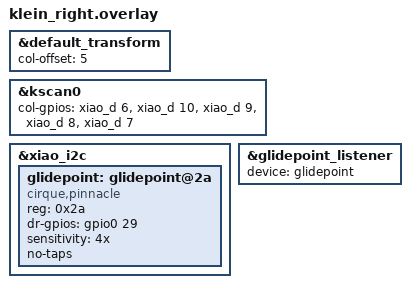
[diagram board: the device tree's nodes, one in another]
/*
 * Copyright (c) 2020 Derek Schmell
 *
 * SPDX-License-Identifier: MIT
 */

#include "klein.dtsi"

&default_transform {
	col-offset = <5>;
};

&kscan0 {
    col-gpios
        = <&xiao_d 6  (GPIO_ACTIVE_HIGH | GPIO_PULL_DOWN)>
        , <&xiao_d 10  (GPIO_ACTIVE_HIGH | GPIO_PULL_DOWN)>
        , <&xiao_d 9  (GPIO_ACTIVE_HIGH | GPIO_PULL_DOWN)>
        , <&xiao_d 8  (GPIO_ACTIVE_HIGH | GPIO_PULL_DOWN)>
        , <&xiao_d 7  (GPIO_ACTIVE_HIGH | GPIO_PULL_DOWN)>
        ;
};

// &xiao_i2c {
//     status = "okay";
//     glidepoint: glidepoint@2a {
//         status = "okay";
//     };
// };

&xiao_i2c {
    status = "okay";
    glidepoint: glidepoint@2a {
        compatible = "cirque,pinnacle";
        reg = <0x2a>;
        status = "okay";
        dr-gpios = <&gpio0 29 (GPIO_ACTIVE_HIGH)>; //this is my setting
        // dr-gpios = <&gpio0 9 (GPIO_ACTIVE_HIGH)>; //this is original setting
        sensitivity = "4x";
        // sleep;
        no-taps;
    };
};
&glidepoint_listener {
    status = "okay";
    device = <&glidepoint>;
};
